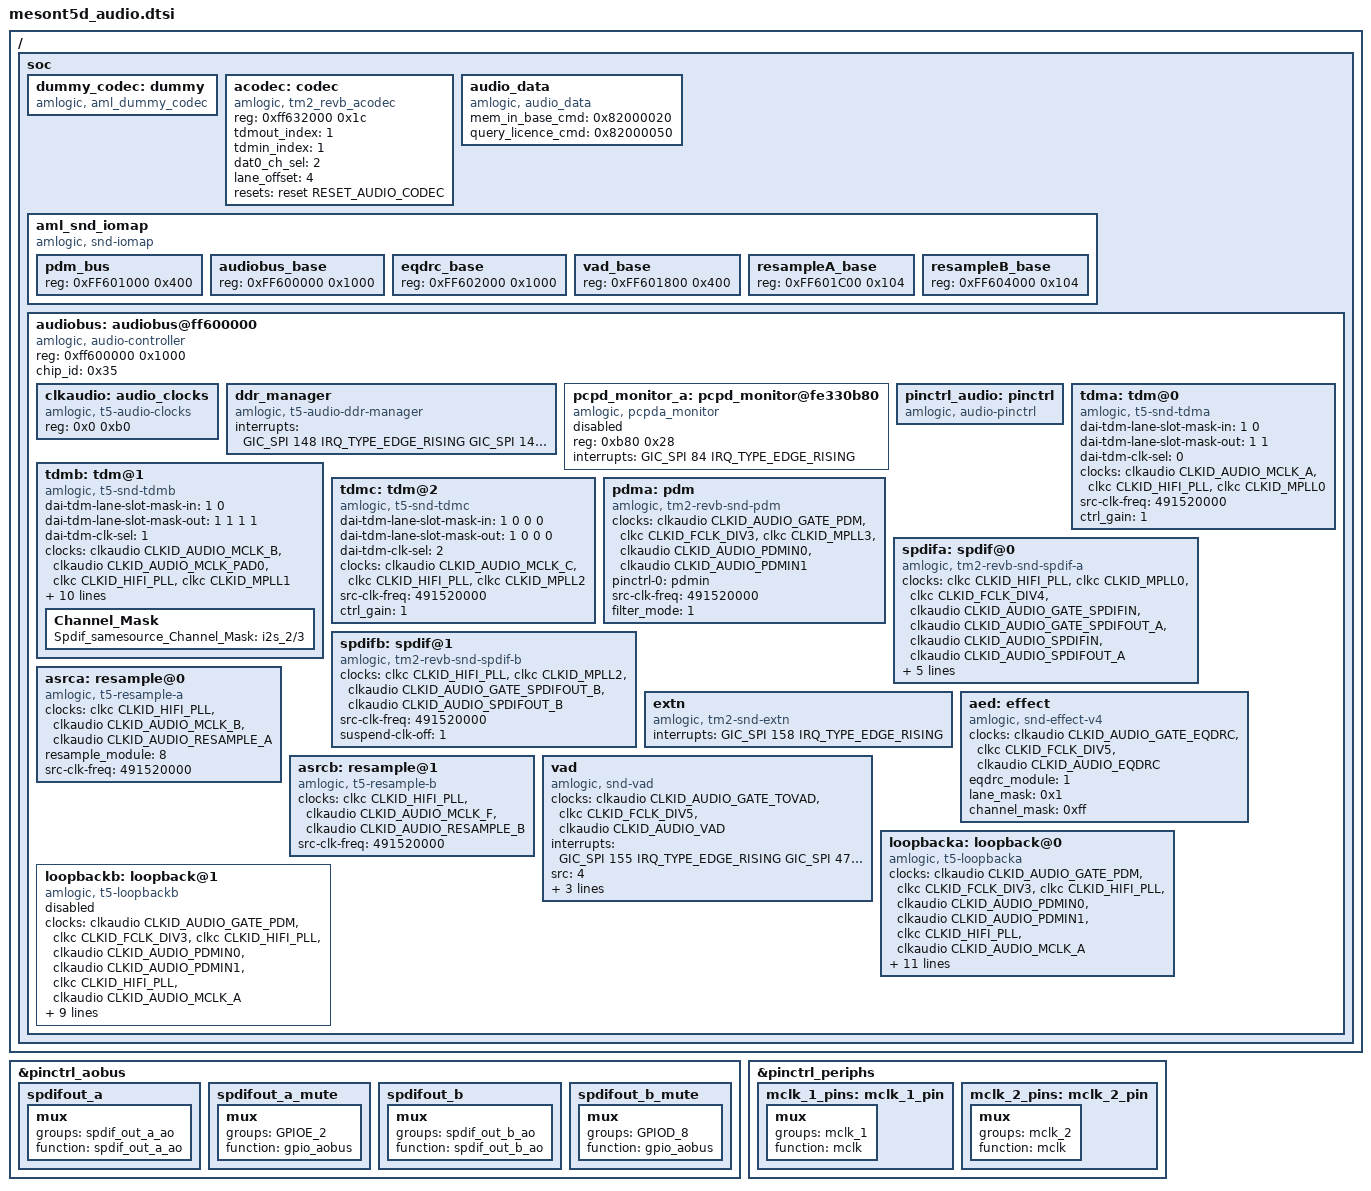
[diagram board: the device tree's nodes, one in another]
// SPDX-License-Identifier: (GPL-2.0+ OR MIT)
/*
 * Copyright (c) 2019 Amlogic, Inc. All rights reserved.
 */

#include <dt-bindings/clock/amlogic,t5-audio-clk.h>
/ {
	soc {
		dummy_codec:dummy{
			#sound-dai-cells = <0>;
			compatible = "amlogic, aml_dummy_codec";
			status = "okay";
		};
		acodec:codec {
			#sound-dai-cells = <0>;
			compatible = "amlogic, tm2_revb_acodec";
			status = "okay";
			reg = <0xff632000 0x1c>;
			tdmout_index = <1>;
			tdmin_index = <1>;
			dat0_ch_sel = <2>;
			lane_offset = <4>;
			reset-names = "acodec";
			resets = <&reset RESET_AUDIO_CODEC>;
		};

		audio_data: audio_data {
			compatible = "amlogic, audio_data";
			mem_in_base_cmd = <0x82000020>;
			query_licence_cmd = <0x82000050>;
			status = "okay";
		};

		/* Sound iomap */
		aml_snd_iomap {
			compatible = "amlogic, snd-iomap";
			status = "okay";
			#address-cells=<1>;
			#size-cells=<1>;
			ranges;
			pdm_bus {
				reg = <0xFF601000 0x400>;
			};
			audiobus_base {
				reg = <0xFF600000 0x1000>;
			};
			eqdrc_base {
				reg = <0xFF602000 0x1000>;
			};
			vad_base {
				reg = <0xFF601800 0x400>;
			};
			resampleA_base {
				reg = <0xFF601C00 0x104>;
			};
			resampleB_base {
				reg = <0xFF604000 0x104>;
			};
		};
		audiobus: audiobus@ff600000 {
			compatible = "amlogic, audio-controller", "simple-bus";
			reg = <0xff600000 0x1000>;
			reg-names = "audio_bus";
			#address-cells = <1>;
			#size-cells = <1>;
			ranges = <0x0 0xff600000 0x1000>;
			chip_id = <0x35>;
			status = "okay";

			clkaudio: audio_clocks {
				compatible = "amlogic, t5-audio-clocks";
				#clock-cells = <1>;
				reg = <0x0 0xb0>;
				status = "okay";
			};
			ddr_manager {
				compatible =
					"amlogic, t5-audio-ddr-manager";
				interrupts = <
					GIC_SPI 148 IRQ_TYPE_EDGE_RISING
					GIC_SPI 149 IRQ_TYPE_EDGE_RISING
					GIC_SPI 150 IRQ_TYPE_EDGE_RISING
					GIC_SPI 48 IRQ_TYPE_EDGE_RISING
					GIC_SPI 152 IRQ_TYPE_EDGE_RISING
					GIC_SPI 153 IRQ_TYPE_EDGE_RISING
					GIC_SPI 154 IRQ_TYPE_EDGE_RISING
					GIC_SPI 49 IRQ_TYPE_EDGE_RISING
				>;
				interrupt-names =
					"toddr_a", "toddr_b", "toddr_c",
					"toddr_d",
					"frddr_a", "frddr_b", "frddr_c",
					"frddr_d";
			};
			pcpd_monitor_a: pcpd_monitor@fe330b80 {
				compatible = "amlogic, pcpda_monitor";
				/*regbase:0xFE330000 + 0x2e0 << 2*/
				/*size 0x28 byte*/
				reg =<0xb80 0x28>;
				reg-names = "pcpd_reg";
				interrupts = <GIC_SPI 84
					IRQ_TYPE_EDGE_RISING>;
				interrupt-names = "irq_pcpd";
				status = "disabled";
			};
			pinctrl_audio: pinctrl {
				compatible = "amlogic, audio-pinctrl";
				status = "okay";
			};
		};/* end of audiobus*/
	};/*end soc*/
};

&audiobus {
	tdma:tdm@0 {
		compatible = "amlogic, t5-snd-tdma";
		#sound-dai-cells = <0>;

		dai-tdm-lane-slot-mask-in = <1 0>;
		dai-tdm-lane-slot-mask-out = <1 1>;
		dai-tdm-clk-sel = <0>;

		clocks = <&clkaudio CLKID_AUDIO_MCLK_A
				&clkc CLKID_HIFI_PLL
				&clkc CLKID_MPLL0>;
		clock-names = "mclk", "clk_srcpll", "clk_src_cd";
		src-clk-freq = <491520000>;
		/* enable control gain */
		ctrl_gain = <1>;

		status = "okay";
	};

	tdmb:tdm@1 {
		compatible = "amlogic, t5-snd-tdmb";
		#sound-dai-cells = <0>;

		dai-tdm-lane-slot-mask-in = <1 0>;
		dai-tdm-lane-slot-mask-out = <1 1 1 1>;
		dai-tdm-clk-sel = <1>;

		clocks = <&clkaudio CLKID_AUDIO_MCLK_B
				&clkaudio CLKID_AUDIO_MCLK_PAD0
				&clkc CLKID_HIFI_PLL
				&clkc CLKID_MPLL1>;
		clock-names = "mclk", "mclk_pad", "clk_srcpll", "clk_src_cd";
		src-clk-freq = <491520000>;

		/*
		 * 0: tdmout_a;
		 * 1: tdmout_b;
		 * 2: tdmout_c;
		 * 3: spdifout;
		 * 4: spdifout_b;
		 */
		samesource_sel = <3>;

		pinctrl-names = "tdm_pins","tdmout_a_gpio";
		pinctrl-0 = <&mclk_1_pins
			&tdmout_b_pins
			&tdm_d0_pins
			&tdm_clk_pins>;
		pinctrl-1 = <&tdmout_a_gpio>;

		/* In for ACODEC_ADC */
		tdmin-src-name = "acodec_adc";
		/*enable default mclk(12.288M), before extern codec start*/
		start_clk_enable = <1>;

		/*tdm clk tuning enable*/
		clk_tuning_enable = <1>;

		/* enable control gain */
		ctrl_gain = <1>;

		/* suspend disable clk */
		suspend-clk-off = <1>;

		status = "okay";

		/* !!!For --TV platform-- ONLY */
		Channel_Mask {
			/*i2s has 4 pins, 8channel, mux output*/
			Spdif_samesource_Channel_Mask = "i2s_2/3";
		};
	};

	tdmc:tdm@2 {
		compatible = "amlogic, t5-snd-tdmc";
		#sound-dai-cells = <0>;

		dai-tdm-lane-slot-mask-in = <1 0 0 0>;
		dai-tdm-lane-slot-mask-out = <1 0 0 0>;
		dai-tdm-clk-sel = <2>;

		clocks = <&clkaudio CLKID_AUDIO_MCLK_C
				&clkc CLKID_HIFI_PLL
				&clkc CLKID_MPLL2>;
		clock-names = "mclk", "clk_srcpll", "clk_src_cd";
		src-clk-freq = <491520000>;
		/* enable control gain */
		ctrl_gain = <1>;

		status = "okay";
	};

	pdma:pdm {
		compatible = "amlogic, tm2-revb-snd-pdm";
		#sound-dai-cells = <0>;

		clocks = <&clkaudio CLKID_AUDIO_GATE_PDM
			&clkc CLKID_FCLK_DIV3
			&clkc CLKID_MPLL3
			&clkaudio CLKID_AUDIO_PDMIN0
			&clkaudio CLKID_AUDIO_PDMIN1>;
		clock-names = "gate",
			"sysclk_srcpll",
			"dclk_srcpll",
			"pdm_dclk",
			"pdm_sysclk";

		pinctrl-names = "pdm_pins";
		pinctrl-0 = <&pdmin>;
		src-clk-freq = <491520000>;
		/* mode 0~4, defalut:1 */
		filter_mode = <1>;

		status = "okay";
	};

	spdifa:spdif@0 {
		compatible = "amlogic, tm2-revb-snd-spdif-a";
		#sound-dai-cells = <0>;

		clocks = <&clkc CLKID_HIFI_PLL
				&clkc CLKID_MPLL0
				&clkc CLKID_FCLK_DIV4
				&clkaudio CLKID_AUDIO_GATE_SPDIFIN
				&clkaudio CLKID_AUDIO_GATE_SPDIFOUT_A
				&clkaudio CLKID_AUDIO_SPDIFIN
				&clkaudio CLKID_AUDIO_SPDIFOUT_A>;
		clock-names = "sysclk", "clk_src_cd", "fixed_clk", "gate_spdifin",
				"gate_spdifout", "clk_spdifin", "clk_spdifout";

		interrupts =
				<GIC_SPI 151 IRQ_TYPE_EDGE_RISING>;
		interrupt-names = "irq_spdifin";
		samesource_sel = <4>;
		src-clk-freq = <491520000>;

		/* suspend disable clk */
		suspend-clk-off = <1>;

		/*spdif clk tuning enable*/
		clk_tuning_enable = <1>;
		status = "okay";
	};

	spdifb:spdif@1 {
		compatible = "amlogic, tm2-revb-snd-spdif-b";
		#sound-dai-cells = <0>;
		clocks = <&clkc CLKID_HIFI_PLL
				&clkc CLKID_MPLL2 /*CLKID_HIFI_PLL*/
				&clkaudio CLKID_AUDIO_GATE_SPDIFOUT_B
				&clkaudio CLKID_AUDIO_SPDIFOUT_B>;
		clock-names = "sysclk", "clk_src_cd",
				"gate_spdifout", "clk_spdifout";

		src-clk-freq = <491520000>;
		/* suspend disable clk */
		suspend-clk-off = <1>;

		status = "okay";
	};

	extn:extn {
		compatible = "amlogic, tm2-snd-extn";
		#sound-dai-cells = <0>;

		interrupts =
				<GIC_SPI 158 IRQ_TYPE_EDGE_RISING>;
		interrupt-names = "irq_frhdmirx";

		status = "okay";
	};

	aed:effect {
		compatible = "amlogic, snd-effect-v4";
		#sound-dai-cells = <0>;

		clocks = <&clkaudio CLKID_AUDIO_GATE_EQDRC
			&clkc CLKID_FCLK_DIV5
			&clkaudio CLKID_AUDIO_EQDRC>;
		clock-names = "gate", "srcpll", "eqdrc";

		/*
		 * 0:tdmout_a
		 * 1:tdmout_b
		 * 2:tdmout_c
		 * 3:spdifout
		 * 4:spdifout_b
		 */
		eqdrc_module = <1>;
		/* max 0xf, each bit for one lane, usually one lane */
		lane_mask = <0x1>;
		/* max 0xff, each bit for one channel */
		channel_mask = <0xff>;

		status = "okay";
	};

	asrca: resample@0 {
		compatible = "amlogic, t5-resample-a";
		clocks = <&clkc CLKID_HIFI_PLL
			&clkaudio CLKID_AUDIO_MCLK_B
			&clkaudio CLKID_AUDIO_RESAMPLE_A>;
		clock-names = "resample_pll", "resample_src", "resample_clk";

		/*same with toddr_src
		 *	TDMIN_A,    0
		 *	TDMIN_B,    1
		 *	TDMIN_C,    2
		 *	SPDIFIN,    3
		 *	PDMIN,      4
		 *	FRATV,      5
		 *	TDMIN_LB,   6
		 *	LOOPBACK_A, 7
		 *	FRHDMIRX,   8
		 *	LOOPBACK_B, 9
		 *	SPDIFIN_LB, 10
		 *	EARC_RX,    11
		 */
		resample_module = <8>;
		src-clk-freq = <491520000>;
		status = "okay";
	};

	asrcb: resample@1 {
		compatible = "amlogic, t5-resample-b";
		clocks = <&clkc CLKID_HIFI_PLL
			&clkaudio CLKID_AUDIO_MCLK_F
			&clkaudio CLKID_AUDIO_RESAMPLE_B>;
		clock-names = "resample_pll", "resample_src", "resample_clk";

		/*this resample is only used for loopback_A.*/
		src-clk-freq = <491520000>;
		status = "okay";
	};

	vad:vad {
		compatible = "amlogic, snd-vad";
		#sound-dai-cells = <0>;

		clocks = <&clkaudio CLKID_AUDIO_GATE_TOVAD
			&clkc CLKID_FCLK_DIV5
			&clkaudio CLKID_AUDIO_VAD>;
		clock-names = "gate", "pll", "clk";

		interrupts = <GIC_SPI 155 IRQ_TYPE_EDGE_RISING
				GIC_SPI 47 IRQ_TYPE_EDGE_RISING>;
		interrupt-names = "irq_wakeup", "irq_frame_sync";

		/*
		 * Data src sel:
		 * 0: tdmin_a;
		 * 1: tdmin_b;
		 * 2: tdmin_c;
		 * 3: spdifin;
		 * 4: pdmin;
		 * 5: loopback_b;
		 * 6: tdmin_lb;
		 * 7: loopback_a;
		 */
		src = <4>;

		/*
		 * deal with hot word in user space or kernel space
		 * 0: in user space
		 * 1: in kernel space
		 */
		level = <1>;

		mic-src = <&pdma>;
		wakeup_sample_rate = <16000>;

		status = "okay";
	};

	loopbacka:loopback@0 {
		compatible = "amlogic, t5-loopbacka";
		#sound-dai-cells = <0>;

		clocks = <&clkaudio CLKID_AUDIO_GATE_PDM
			&clkc CLKID_FCLK_DIV3
			&clkc CLKID_HIFI_PLL
			&clkaudio CLKID_AUDIO_PDMIN0
			&clkaudio CLKID_AUDIO_PDMIN1
			&clkc CLKID_HIFI_PLL
			&clkaudio CLKID_AUDIO_MCLK_A>;
		clock-names = "pdm_gate",
			"pdm_sysclk_srcpll",
			"pdm_dclk_srcpll",
			"pdm_dclk",
			"pdm_sysclk",
			"tdminlb_mpll",
			"tdminlb_mclk";

		/* datain src
		 * 0: tdmin_a;
		 * 1: tdmin_b;
		 * 2: tdmin_c;
		 * 3: spdifin;
		 * 4: pdmin;
		 */
		datain_src = <4>;
		datain_chnum = <4>;
		datain_chmask = <0xf>;
		/* config which data pin for loopback */
		datain-lane-mask-in = <1 1 0 0>;

		/* calc mclk for datalb */
		mclk-fs = <256>;

		/* tdmin_lb src
		 * 0: tdmoutA
		 * 1: tdmoutB
		 * 2: tdmoutC
		 * 3: PAD_TDMINA_DIN*, refer to core pinmux
		 * 4: PAD_TDMINB_DIN*, refer to core pinmux
		 * 5: PAD_TDMINC_DIN*, refer to core pinmux
		 * 6: PAD_TDMINA_D*, oe, refer to core pinmux
		 * 7: PAD_TDMINB_D*, oe, refer to core pinmux
		 */
		/* if tdmin_lb >= 3, use external loopback */
		datalb_src = <1>;
		datalb_chnum = <2>;
		datalb_chmask = <0x3>;
		/* config which data pin as loopback */
		datalb-lane-mask-in = <1 0 0 0>;

		/* define loopack with pdm mic. */
		mic-src = <&pdma>;
		src-clk-freq = <491520000>;
		status = "okay";
	};

	loopbackb:loopback@1 {
		compatible = "amlogic, t5-loopbackb";
		#sound-dai-cells = <0>;

		clocks = <&clkaudio CLKID_AUDIO_GATE_PDM
			&clkc CLKID_FCLK_DIV3
			&clkc CLKID_HIFI_PLL
			&clkaudio CLKID_AUDIO_PDMIN0
			&clkaudio CLKID_AUDIO_PDMIN1
			&clkc CLKID_HIFI_PLL
			&clkaudio CLKID_AUDIO_MCLK_A>;
		clock-names = "pdm_gate",
			"pdm_sysclk_srcpll",
			"pdm_dclk_srcpll",
			"pdm_dclk",
			"pdm_sysclk",
			"tdminlb_mpll",
			"tdminlb_mclk";

		/* calc mclk for datain_lb */
		mclk-fs = <256>;

		/* datain src
		 * 0: tdmin_a;
		 * 1: tdmin_b;
		 * 2: tdmin_c;
		 * 3: spdifin;
		 * 4: pdmin;
		 */
		datain_src = <4>;
		datain_chnum = <4>;
		datain_chmask = <0xf>;
		/* config which data pin for loopback */
		datain-lane-mask-in = <1 0 1 0>;

		/* tdmin_lb src
		 * 0: tdmoutA
		 * 1: tdmoutB
		 * 2: tdmoutC
		 * 3: PAD_TDMINA_DIN*, refer to core pinmux
		 * 4: PAD_TDMINB_DIN*, refer to core pinmux
		 * 5: PAD_TDMINC_DIN*, refer to core pinmux
		 * 6: PAD_TDMINA_D*, oe, refer to core pinmux
		 * 7: PAD_TDMINB_D*, oe, refer to core pinmux
		 */
		/* if tdmin_lb >= 3, use external loopback */
		datalb_src = <1>;
		datalb_chnum = <2>;
		datalb_chmask = <0x3>;
		/* config which data pin as loopback */
		datalb-lane-mask-in = <1 0 0 0>;

		status = "disabled";
	};
}; /* end of audiobus */

&pinctrl_aobus {
	spdifout_a: spdifout_a {
		mux { /* GPIOE_2 */
			groups = "spdif_out_a_ao";
			function = "spdif_out_a_ao";
		};
	};

	spdifout_a_mute: spdifout_a_mute {
		mux { /* GPIOE_2 */
			groups = "GPIOE_2";
			function = "gpio_aobus";
		};
	};

	spdifout_b: spdifout_b {
		mux { /* GPIOD_8 */
			groups = "spdif_out_b_ao";
			function = "spdif_out_b_ao";
		};
	};

	spdifout_b_mute: spdifout_b_mute {
		mux { /* GPIOD_8 */
			groups = "GPIOD_8";
			function = "gpio_aobus";
		};
	};
};

&pinctrl_periphs {
	mclk_1_pins: mclk_1_pin {
		mux { /* GPIOH_14 */
			groups = "mclk_1";
			function = "mclk";
		};
	};

	mclk_2_pins: mclk_2_pin {
		mux { /* GPIOZ_6 */
			groups = "mclk_2";
			function = "mclk";
		};
	};
};
